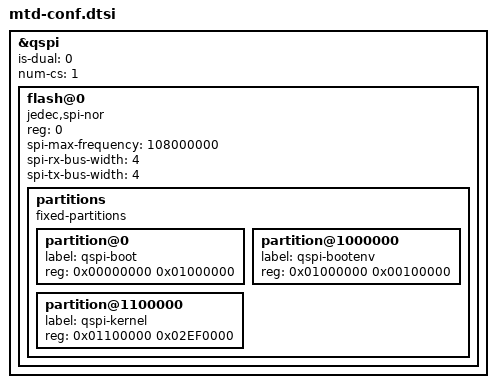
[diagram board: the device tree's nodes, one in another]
/ {
};

&qspi {
    status = "okay";
    is-dual = <0>;
    num-cs = <1>;
    #address-cells = <1>;
    #size-cells = <0>;

    flash@0 {
        compatible = "jedec,spi-nor";
        reg = <0>;
        spi-max-frequency = <108000000>;
        spi-rx-bus-width = <4>;
        spi-tx-bus-width = <4>;

        partitions {
            compatible = "fixed-partitions";
            #address-cells = <1>;
            #size-cells = <1>;

            partition@0 {
                label = "qspi-boot";
                reg = <0x00000000 0x01000000>; /* first 16MB */
            };
            partition@1000000 {
                label = "qspi-bootenv";
                reg = <0x01000000 0x00100000>; /* 16MB-17MB */
            };
            partition@1100000 {
                label = "qspi-kernel";
                reg = <0x01100000 0x02EF0000>; /* 17MB - 64MB */
            };
        };
    };
};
